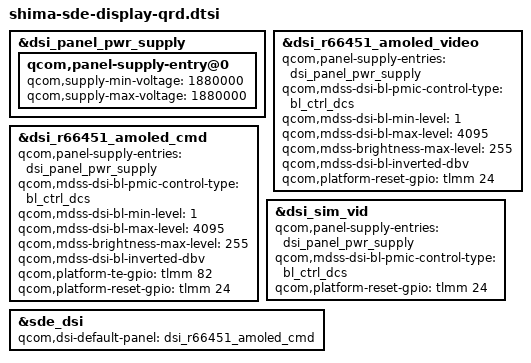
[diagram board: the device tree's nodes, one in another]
#include "shima-sde-display.dtsi"

&dsi_panel_pwr_supply {
	qcom,panel-supply-entry@0 {
		qcom,supply-min-voltage = <1880000>;
		qcom,supply-max-voltage = <1880000>;
	};
};

&dsi_r66451_amoled_video {
	qcom,panel-supply-entries = <&dsi_panel_pwr_supply>;
	qcom,mdss-dsi-bl-pmic-control-type = "bl_ctrl_dcs";
	qcom,mdss-dsi-bl-min-level = <1>;
	qcom,mdss-dsi-bl-max-level = <4095>;
	qcom,mdss-brightness-max-level = <255>;
	qcom,mdss-dsi-bl-inverted-dbv;
	qcom,platform-reset-gpio = <&tlmm 24 0>;
};

&dsi_r66451_amoled_cmd {
	qcom,panel-supply-entries = <&dsi_panel_pwr_supply>;
	qcom,mdss-dsi-bl-pmic-control-type = "bl_ctrl_dcs";
	qcom,mdss-dsi-bl-min-level = <1>;
	qcom,mdss-dsi-bl-max-level = <4095>;
	qcom,mdss-brightness-max-level = <255>;
	qcom,mdss-dsi-bl-inverted-dbv;
	qcom,platform-te-gpio = <&tlmm 82 0>;
	qcom,platform-reset-gpio = <&tlmm 24 0>;
};

&dsi_sim_vid {
	qcom,panel-supply-entries = <&dsi_panel_pwr_supply>;
	qcom,mdss-dsi-bl-pmic-control-type = "bl_ctrl_dcs";
	qcom,platform-reset-gpio = <&tlmm 24 0>;
};

&sde_dsi {
	qcom,dsi-default-panel = <&dsi_r66451_amoled_cmd>;
};
